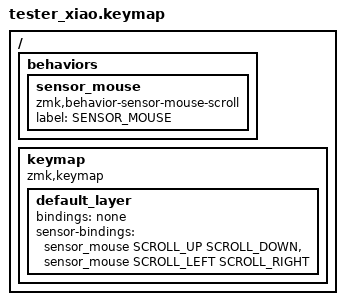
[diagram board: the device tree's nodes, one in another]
#include <behaviors.dtsi>
#include <dt-bindings/zmk/keys.h>
#include <dt-bindings/zmk/mouse.h>

/ {
    behaviors {
        sensor_mouse: sensor_mouse {
            compatible = "zmk,behavior-sensor-mouse-scroll";
            label = "SENSOR_MOUSE";
            #sensor-binding-cells = <2>;
        };
    };

    keymap {
        compatible = "zmk,keymap";

        default_layer {
            bindings = <&none>;

            sensor-bindings = <
                &sensor_mouse SCROLL_UP SCROLL_DOWN
                &sensor_mouse SCROLL_LEFT SCROLL_RIGHT
            >;
        };
    };
};
